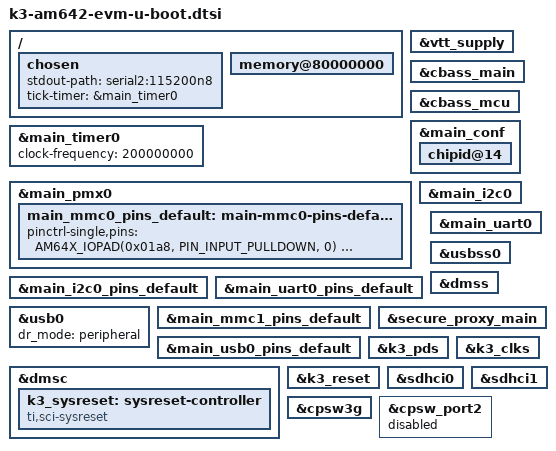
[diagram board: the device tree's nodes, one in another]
// SPDX-License-Identifier: GPL-2.0
/*
 * Copyright (C) 2020-2021 Texas Instruments Incorporated - https://www.ti.com/
 */

#include "k3-am64x-binman.dtsi"

/ {
	chosen {
		stdout-path = "serial2:115200n8";
		tick-timer = &main_timer0;
	};

	memory@80000000 {
		bootph-pre-ram;
	};
};

&vtt_supply {
	bootph-pre-ram;
};

&cbass_main {
	bootph-pre-ram;
};

&cbass_mcu {
	bootph-pre-ram;
};

&main_timer0 {
	bootph-pre-ram;
	clock-frequency = <200000000>;
};

&main_conf {
	bootph-pre-ram;
	chipid@14 {
		bootph-pre-ram;
	};
};

&main_pmx0 {
	bootph-pre-ram;
	/* FIXME: drop mmc0 pinmux when added to k3-am642-evm.dts */
	main_mmc0_pins_default: main-mmc0-pins-default {
		bootph-pre-ram;
		pinctrl-single,pins = <
			AM64X_IOPAD(0x01a8, PIN_INPUT_PULLDOWN, 0)      /* (B25) MMC0_CLK */
			AM64X_IOPAD(0x01aC, PIN_INPUT_PULLUP, 0)        /* (B27) MMC0_CMD */
			AM64X_IOPAD(0x01a4, PIN_INPUT_PULLUP, 0)        /* (A26) MMC0_DAT0 */
			AM64X_IOPAD(0x01a0, PIN_INPUT_PULLUP, 0)        /* (E25) MMC0_DAT1 */
			AM64X_IOPAD(0x019c, PIN_INPUT_PULLUP, 0)        /* (C26) MMC0_DAT2 */
			AM64X_IOPAD(0x0198, PIN_INPUT_PULLUP, 0)        /* (A25) MMC0_DAT3 */
			AM64X_IOPAD(0x0194, PIN_INPUT_PULLUP, 0)        /* (E24) MMC0_DAT4 */
			AM64X_IOPAD(0x0190, PIN_INPUT_PULLUP, 0)        /* (A24) MMC0_DAT5 */
			AM64X_IOPAD(0x018c, PIN_INPUT_PULLUP, 0)        /* (B26) MMC0_DAT6 */
			AM64X_IOPAD(0x0188, PIN_INPUT_PULLUP, 0)        /* (D25) MMC0_DAT7 */
			AM64X_IOPAD(0x01b0, PIN_INPUT, 0)               /* (C25) MMC0_DS */
			>;
	};
};

&main_i2c0_pins_default {
	bootph-pre-ram;
};

&main_i2c0 {
	bootph-pre-ram;
};

&main_uart0_pins_default {
	bootph-pre-ram;
};

&main_uart0 {
	bootph-pre-ram;
};

&usb0 {
	dr_mode="peripheral";
	bootph-pre-ram;
};

&usbss0 {
	bootph-pre-ram;
};

&main_mmc1_pins_default {
	bootph-pre-ram;
};

&main_usb0_pins_default {
	bootph-pre-ram;
};

&dmss {
	bootph-pre-ram;
};

&secure_proxy_main {
	bootph-pre-ram;
};

&dmsc {
	bootph-pre-ram;
	k3_sysreset: sysreset-controller {
		compatible = "ti,sci-sysreset";
		bootph-pre-ram;
	};
};

&k3_pds {
	bootph-pre-ram;
};

&k3_clks {
	bootph-pre-ram;
};

&k3_reset {
	bootph-pre-ram;
};

&sdhci0 {
	bootph-pre-ram;
};

&sdhci1 {
	bootph-pre-ram;
};

&cpsw3g {
	bootph-pre-ram;
};

&cpsw_port2 {
	status = "disabled";
};
